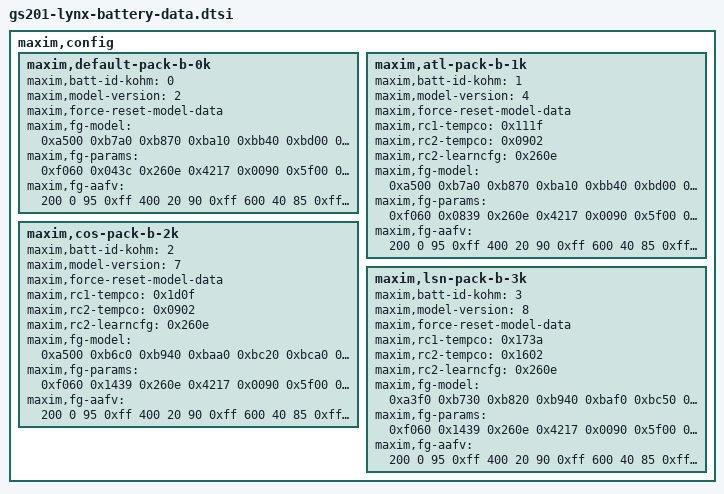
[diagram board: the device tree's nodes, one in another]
// SPDX-License-Identifier: GPL-2.0-only
/*
 * Battery device tree entries
 *
 * Copyright 2022 Google LLC
 *
 */

maxim,config {
	maxim,default-pack-b-0k {
		maxim,batt-id-kohm = <0>;
		maxim,model-version = <2>;
		maxim,force-reset-model-data;
		maxim,fg-model = /bits/ 16 <
			0xa500 0xb7a0 0xb870 0xba10 0xbb40 0xbd00 0xbe40 0xbfe0
			0xc230 0xc430 0xc720 0xca00 0xcdc0 0xd180 0xd5d0 0xdd90
			0x01b0 0x1600 0x0c00 0x0d00 0x1700 0x1300 0x1200 0x0f20
			0x07d0 0x07f0 0x0810 0x06e0 0x06f0 0x07f0 0x04f0 0x04f0
			0x0200 0x0200 0x0200 0x0200 0x0200 0x0200 0x0200 0x0200
			0x0200 0x0200 0x0200 0x0200 0x0200 0x0200 0x0200 0x0200
		>;
		maxim,fg-params = /bits/ 16 <
			/* 0x0036 */	0xf060	/* nIAvgEmpty -> IAvgEmpty */
			/* 0x002a */	0x043c	/* nRelaxCFG -> RelaxCFG */
			/* 0x0028 */	0x260e	/* nLearnCFG -> LearnCFG */
			/* 0x001D */	0x4217	/* Config: */
			/* 0x00BB */	0x0090	/* Config2: OCVQen|DSOCIi */
			/* 0x0013 */	0x5f00	/* nFullSOCThr -> FullSOCThr*/
			/* 0x0035 */	0x088d	/* nFullCapRep */
			/* 0x0018 */	0x088d	/* nDesignCap */
			/* 0x0046 */	0x3200	/* dPacc */
			/* 0x0045 */	0x0223	/* dQacc */
			/* 0x0023 */	0x088d	/* nFullCapNom */
			/* 0x003A */	0xA561	/* V_empty */
			/* 0x0012 */	0x1680	/* nQRTable00 -> QResidual00 */
			/* 0x0022 */	0x0b80	/* nQRTable10 -> QResidual10 */
			/* 0x0032 */	0x0680	/* nQRTable20 -> QResidual20 */
			/* 0x0042 */	0x0500	/* nQRTable30 -> QResidual30 */
			/* 0x0038 */	0x0460	/* nRcomp0 */
			/* 0x0039 */	0x0902	/* nTempco */
			/* 0x001E */	0x0560	/* ICHGTerm */
			/* 0x002C */	0xED51	/* *TGain */
			/* 0x002D */	0x1EBA	/* *TOFF */
			/* 0x00B9 */	0x0014	/* *TCurve */
			/* 0x002B */	0x3870	/* *nMiscCfg */
			/* 0x0004 */	0x1900	/* AtRate @ 0x04 */
			/* 0x0049 */	0x2241	/* convgcfg */
			/* 0x0029 */	0xc615	/* FilterCFG */
			/* 0x003c */	0x2D00	/* TaskPeriod */
			/* 0x002e */	0x0400	/* CGain */
		>;
		maxim,fg-aafv = /bits/ 32 <
			200     0   95  0xff
			400    20   90  0xff
			600    40   85  0xff
			800    60   80  0xff
			1000   80   75  0xff
			2000  130   63  0xff
		>;
	};
	/* 1_L10_ATL_031522_RC2_INI_0830.txt http://b/244371981#comment1 */
	maxim,atl-pack-b-1k {
		maxim,batt-id-kohm = <1>;
		maxim,model-version = <4>;
		maxim,force-reset-model-data;
		maxim,rc1-tempco = /bits/ 16 <0x111f>;
		maxim,rc2-tempco = /bits/ 16 <0x0902>;
		maxim,rc2-learncfg = /bits/ 16 <0x260e>;
		maxim,fg-model = /bits/ 16 <
			0xa500 0xb7a0 0xb870 0xba10 0xbb40 0xbd00 0xbe40 0xbfe0
			0xc230 0xc430 0xc720 0xca00 0xcdc0 0xd180 0xd5d0 0xdd90
			0x01b0 0x1600 0x0c00 0x0d00 0x1700 0x1300 0x1200 0x0f20
			0x07d0 0x07f0 0x0810 0x06e0 0x06f0 0x07f0 0x04f0 0x04f0
			0x0200 0x0200 0x0200 0x0200 0x0200 0x0200 0x0200 0x0200
			0x0200 0x0200 0x0200 0x0200 0x0200 0x0200 0x0200 0x0200
		>;
		maxim,fg-params = /bits/ 16 <
			/* 0x0036 */	0xf060	/* nIAvgEmpty -> IAvgEmpty */
			/* 0x002a */	0x0839	/* nRelaxCFG -> RelaxCFG */
			/* 0x0028 */	0x260e	/* nLearnCFG -> LearnCFG */
			/* 0x001D */	0x4217	/* Config: */
			/* 0x00BB */	0x0090	/* Config2: OCVQen|DSOCIi */
			/* 0x0013 */	0x5f00	/* nFullSOCThr -> FullSOCThr*/
			/* 0x0035 */	0x088d	/* nFullCapRep */
			/* 0x0018 */	0x088d	/* nDesignCap */
			/* 0x0046 */	0x3200	/* dPacc */
			/* 0x0045 */	0x0223	/* dQacc */
			/* 0x0023 */	0x088d	/* nFullCapNom */
			/* 0x003A */	0xA561	/* V_empty */
			/* 0x0012 */	0x1680	/* nQRTable00 -> QResidual00 */
			/* 0x0022 */	0x0b80	/* nQRTable10 -> QResidual10 */
			/* 0x0032 */	0x0680	/* nQRTable20 -> QResidual20 */
			/* 0x0042 */	0x0500	/* nQRTable30 -> QResidual30 */
			/* 0x0038 */	0x0460	/* nRcomp0 */
			/* 0x0039 */	0x0902	/* nTempco */
			/* 0x001E */	0x0560	/* ICHGTerm */
			/* 0x002C */	0xED51	/* *TGain */
			/* 0x002D */	0x1EBA	/* *TOFF */
			/* 0x00B9 */	0x0014	/* *TCurve */
			/* 0x002B */	0x3870	/* *nMiscCfg */
			/* 0x0004 */	0x1900	/* AtRate @ 0x04 */
			/* 0x0049 */	0x2241	/* convgcfg */
			/* 0x0029 */	0xc613	/* FilterCFG */
			/* 0x003c */	0x2D00	/* TaskPeriod */
			/* 0x002e */	0x0400	/* CGain */
		>;
		maxim,fg-aafv = /bits/ 32 <
			200     0   95  0xff
			400    20   90  0xff
			600    40   85  0xff
			800    60   80  0xff
			1000   80   75  0xff
			2000  130   63  0xff
		>;
	};
	/* 2_L10_COS_031622_RC2_INI_Rev7.txt http://b/323608826#comment10 */
	maxim,cos-pack-b-2k {
		maxim,batt-id-kohm = <2>;
		maxim,model-version = <7>;
		maxim,force-reset-model-data;
		maxim,rc1-tempco = /bits/ 16 <0x1d0f>;
		maxim,rc2-tempco = /bits/ 16 <0x0902>;
		maxim,rc2-learncfg = /bits/ 16 <0x260e>;
		maxim,fg-model = /bits/ 16 <
			0xa500 0xb6c0 0xb940 0xbaa0 0xbc20 0xbca0 0xbed0 0xc010
			0xc190 0xc430 0xc7c0 0xcac0 0xcdf0 0xd160 0xd5b0 0xddb0
			0x01d0 0x0810 0x1100 0x1300 0x1900 0x1300 0x1400 0x0e30
			0x0a10 0x0710 0x06e0 0x07f0 0x06f0 0x07f0 0x04f0 0x04f0
			0x0200 0x0200 0x0200 0x0200 0x0200 0x0200 0x0200 0x0200
			0x0200 0x0200 0x0200 0x0200 0x0200 0x0200 0x0200 0x0200
		>;
		maxim,fg-params = /bits/ 16 <
			/* 0x0036 */	0xf060	/* nIAvgEmpty -> IAvgEmpty */
			/* 0x002a */	0x1439	/* nRelaxCFG -> RelaxCFG */
			/* 0x0028 */	0x260e	/* nLearnCFG -> LearnCFG */
			/* 0x001D */	0x4217	/* Config: */
			/* 0x00BB */	0x0090	/* Config2: OCVQen|DSOCIi */
			/* 0x0013 */	0x5f00	/* nFullSOCThr -> FullSOCThr*/
			/* 0x0035 */	0x08A2	/* nFullCapRep */
			/* 0x0018 */	0x08A2	/* nDesignCap */
			/* 0x0046 */	0x3200	/* dPacc */
			/* 0x0045 */	0x0228	/* dQacc */
			/* 0x0023 */	0x08A2	/* nFullCapNom */
			/* 0x003A */	0xA561	/* V_empty */
			/* 0x0012 */	0x1900	/* nQRTable00 -> QResidual00 */
			/* 0x0022 */	0x0b80	/* nQRTable10 -> QResidual10 */
			/* 0x0032 */	0x0500	/* nQRTable20 -> QResidual20 */
			/* 0x0042 */	0x0480	/* nQRTable30 -> QResidual30 */
			/* 0x0038 */	0x07a0	/* nRcomp0 */
			/* 0x0039 */	0x0902	/* nTempco */
			/* 0x001E */	0x0560	/* ICHGTerm */
			/* 0x002C */	0xED51	/* *TGain */
			/* 0x002D */	0x1EBA	/* *TOFF */
			/* 0x00B9 */	0x0014	/* *TCurve */
			/* 0x002B */	0x6070	/* *nMiscCfg */
			/* 0x0004 */	0x1900	/* AtRate @ 0x04 */
			/* 0x0049 */	0x2241	/* convgcfg */
			/* 0x0029 */	0xc613	/* FilterCFG */
			/* 0x003c */	0x2D00	/* TaskPeriod */
			/* 0x002e */	0x0400	/* CGain */
		>;
		maxim,fg-aafv = /bits/ 32 <
			200     0   95  0xff
			400    20   90  0xff
			600    40   85  0xff
			800    60   80  0xff
			1000   80   75  0xff
			2000  130   63  0xff
		>;
	};
	/* 3_L10_LSN_061322_RC2_INI_Rev8.txt http://b/323608826#comment10 */
	maxim,lsn-pack-b-3k {
		maxim,batt-id-kohm = <3>;
		maxim,model-version = <8>;
		maxim,force-reset-model-data;
		maxim,rc1-tempco = /bits/ 16 <0x173a>;
		maxim,rc2-tempco = /bits/ 16 <0x1602>;
		maxim,rc2-learncfg = /bits/ 16 <0x260e>;
		maxim,fg-model = /bits/ 16 <
			0xa3f0 0xb730 0xb820 0xb940 0xbaf0 0xbc50 0xbda0 0xbe90
			0xbff0 0xc270 0xc5d0 0xc930 0xcfd0 0xd350 0xd700 0xdd00
			0x0140 0x0c20 0x0e10 0x0f10 0x1210 0x1310 0x1d10 0x1200
			0x0e10 0x07d0 0x07f0 0x06d0 0x0760 0x06f0 0x05f0 0x05f0
			0x0200 0x0200 0x0200 0x0200 0x0200 0x0200 0x0200 0x0200
			0x0200 0x0200 0x0200 0x0200 0x0200 0x0200 0x0200 0x0200
		>;
		maxim,fg-params = /bits/ 16 <
			/* 0x0036 */	0xf060	/* nIAvgEmpty -> IAvgEmpty */
			/* 0x002a */	0x1439	/* nRelaxCFG -> RelaxCFG */
			/* 0x0028 */	0x260e	/* nLearnCFG -> LearnCFG */
			/* 0x001D */	0x4217	/* Config: */
			/* 0x00BB */	0x0090	/* Config2: OCVQen|DSOCIi */
			/* 0x0013 */	0x5f00	/* nFullSOCThr -> FullSOCThr*/
			/* 0x0035 */	0x08a9	/* nFullCapRep */
			/* 0x0018 */	0x08a9	/* nDesignCap */
			/* 0x0046 */	0x3200	/* dPacc */
			/* 0x0045 */	0x022a	/* dQacc */
			/* 0x0023 */	0x08a9	/* nFullCapNom */
			/* 0x003A */	0xA561	/* V_empty */
			/* 0x0012 */	0x2200	/* nQRTable00 -> QResidual00 */
			/* 0x0022 */	0x1000	/* nQRTable10 -> QResidual10 */
			/* 0x0032 */	0x0780	/* nQRTable20 -> QResidual20 */
			/* 0x0042 */	0x0580	/* nQRTable30 -> QResidual30 */
			/* 0x0038 */	0x0760	/* nRcomp0 */
			/* 0x0039 */	0x1602	/* nTempco */
			/* 0x001E */	0x0560	/* ICHGTerm */
			/* 0x002C */	0xED51	/* *TGain */
			/* 0x002D */	0x1EBA	/* *TOFF */
			/* 0x00B9 */	0x0014	/* *TCurve */
			/* 0x002B */	0x6070	/* *nMiscCfg */
			/* 0x0004 */	0x1900	/* AtRate @ 0x04 */
			/* 0x0049 */	0x2241	/* convgcfg */
			/* 0x0029 */	0xc613	/* FilterCFG */
			/* 0x003c */	0x2D00	/* TaskPeriod */
			/* 0x002e */	0x0400	/* CGain */
		>;
		maxim,fg-aafv = /bits/ 32 <
			200     0   95  0xff
			400    20   90  0xff
			600    40   85  0xff
			800    60   80  0xff
			1000   80   75  0xff
			2000  130   63  0xff
		>;
	};

};
